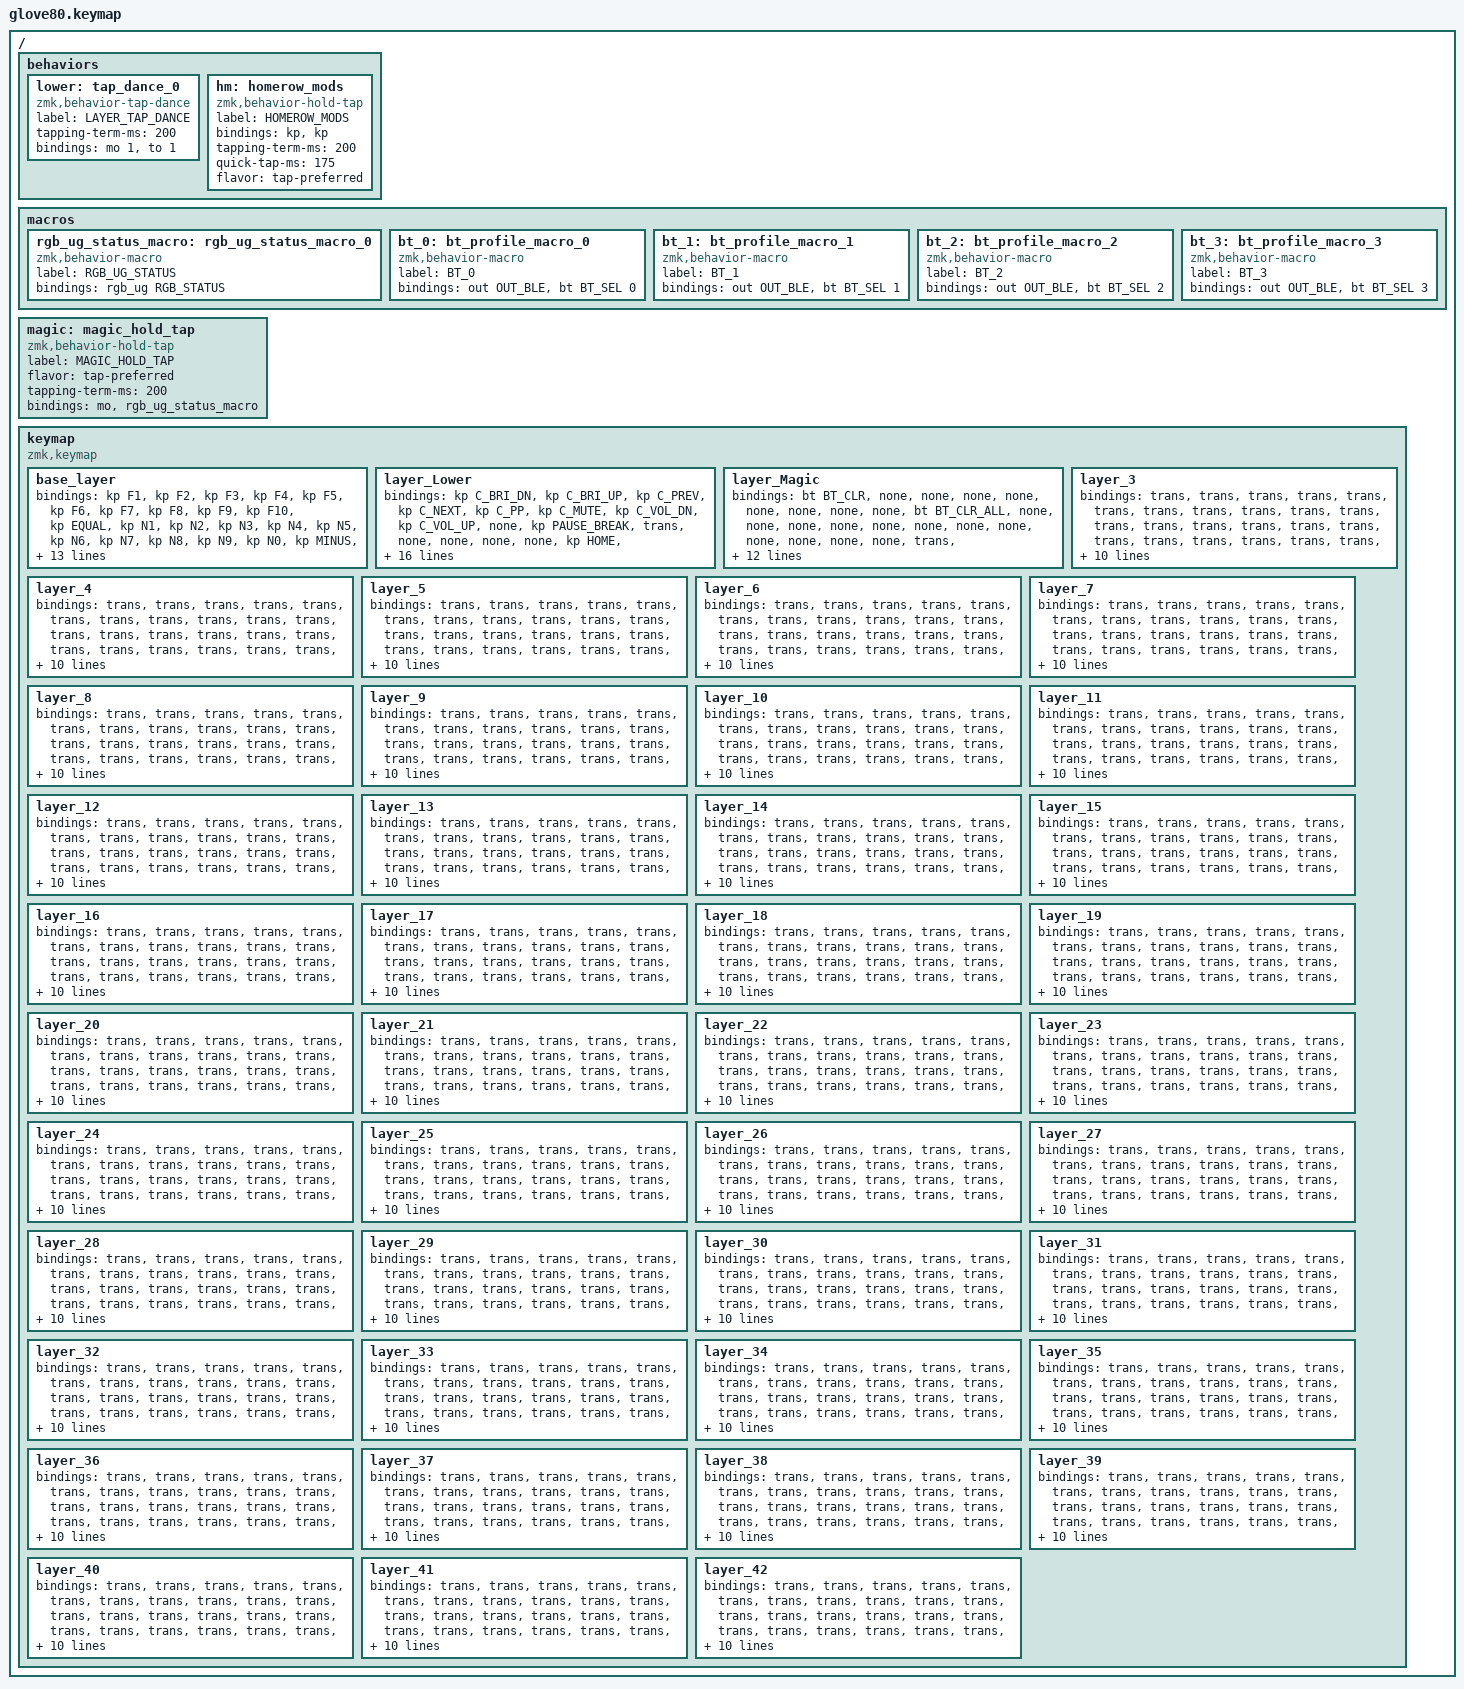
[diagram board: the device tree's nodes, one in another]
/*
 * Copyright (c) 2020 The ZMK Contributors
 * Copyright (c) 2022 Innaworks Development Limited, trading as MoErgo
 *
 * SPDX-License-Identifier: MIT
 */
/* THIS FILE WAS GENERATED BY GLOVE80 LAYOUT EDITOR
 *
 * This file was generated automatically. You may or may not want to
 * edit it directly.
 */

#include <behaviors.dtsi>

/* Include all behaviour includes needed by system behaviors/macros */
/* Include behaviour includes needed by key binds - automatically generated */

#include <dt-bindings/zmk/bt.h>
#include <dt-bindings/zmk/keys.h>
#include <dt-bindings/zmk/outputs.h>
#include <dt-bindings/zmk/rgb.h>

/ {
    /* Glove80 system behavior & macros */

    behaviors {
        // For the "layer" key, it'd nice to be able to use it as either a shift or a toggle.
        // Configure it as a tap dance, so the first tap (or hold) is a &mo and the second tap is a &to

        lower: tap_dance_0 {
            compatible = "zmk,behavior-tap-dance";
            label = "LAYER_TAP_DANCE";
            #binding-cells = <0>;
            tapping-term-ms = <200>;
            bindings = <&mo 1>, <&to 1>;
        };
        hm: homerow_mods {
            compatible = "zmk,behavior-hold-tap";
            label = "HOMEROW_MODS";
            bindings = <&kp>, <&kp>;

            #binding-cells = <2>;
            tapping-term-ms = <200>;
            quick-tap-ms = <175>;
            flavor = "tap-preferred";
        };
    };

    macros {
        rgb_ug_status_macro: rgb_ug_status_macro_0 {
            label = "RGB_UG_STATUS";
            compatible = "zmk,behavior-macro";
            #binding-cells = <0>;
            bindings = <&rgb_ug RGB_STATUS>;
        };
    };

    macros {
        bt_0: bt_profile_macro_0 {
            label = "BT_0";
            compatible = "zmk,behavior-macro";
            #binding-cells = <0>;
            bindings = <&out OUT_BLE &bt BT_SEL 0>;
        };
    };

    macros {
        bt_1: bt_profile_macro_1 {
            label = "BT_1";
            compatible = "zmk,behavior-macro";
            #binding-cells = <0>;
            bindings = <&out OUT_BLE &bt BT_SEL 1>;
        };
    };

    macros {
        bt_2: bt_profile_macro_2 {
            label = "BT_2";
            compatible = "zmk,behavior-macro";
            #binding-cells = <0>;
            bindings = <&out OUT_BLE &bt BT_SEL 2>;
        };
    };

    macros {
        bt_3: bt_profile_macro_3 {
            label = "BT_3";
            compatible = "zmk,behavior-macro";
            #binding-cells = <0>;
            bindings = <&out OUT_BLE &bt BT_SEL 3>;
        };
    };

    magic: magic_hold_tap {
        compatible = "zmk,behavior-hold-tap";
        label = "MAGIC_HOLD_TAP";
        #binding-cells = <2>;
        flavor = "tap-preferred";
        tapping-term-ms = <200>;
        bindings = <&mo>, <&rgb_ug_status_macro>;
    };

    /* Custom Defined Behaviors */
    /* Automatically generated keymap */

    keymap {
        compatible = "zmk,keymap";

        base_layer {
            bindings = <
&kp F1      &kp F2     &kp F3          &kp F4            &kp F5                                                                                                      &kp F6       &kp F7        &kp F8           &kp F9     &kp F10
&kp EQUAL   &kp N1     &kp N2          &kp N3            &kp N4             &kp N5                                                                           &kp N6  &kp N7       &kp N8        &kp N9           &kp N0     &kp MINUS
&kp TAB     &kp Q      &kp W           &kp E             &kp R              &kp T                                                                            &kp Y   &kp U        &kp I         &kp O            &kp P      &kp BSLH
&kp ESC     &kp A      &hm LEFT_ALT S  &hm LCTRL D       &hm RSHFT F        &kp G                                                                            &kp H   &hm RSHFT J  &hm RCTRL K   &hm RIGHT_ALT L  &kp SEMI   &kp SQT
&kp LSHIFT  &kp Z      &kp X           &kp C             &kp V              &kp B   &kp LCTRL  &kp LEFT_ALT  &lt 1 HOME  &kp PAGE_UP    &kp LGUI  &kp RCTRL  &kp N   &kp M        &kp COMMA     &kp DOT          &kp FSLH   &kp RSHFT
&magic 2 0  &kp GRAVE  &kp CAPSLOCK    &kp LEFT_BRACKET  &kp RIGHT_BRACKET          &kp BSPC   &kp DEL       &kp END     &kp PAGE_DOWN  &kp RET   &kp SPACE          &kp LEFT     &kp UP_ARROW  &kp DOWN         &kp RIGHT  &lower
            >;
        };

        layer_Lower {
            bindings = <
&kp C_BRI_DN  &kp C_BRI_UP  &kp C_PREV      &kp C_NEXT      &kp C_PP                                                                                           &kp C_MUTE  &kp C_VOL_DN  &kp C_VOL_UP  &none            &kp PAUSE_BREAK
&trans        &none         &none           &none           &none            &kp HOME                                                   &kp LEFT_PARENTHESIS   &kp KP_NUM  &kp KP_EQUAL  &kp KP_SLASH  &kp KP_MULTIPLY  &kp PRINTSCREEN
&trans        &none         &none           &kp UP_ARROW    &none            &kp END                                                    &kp RIGHT_PARENTHESIS  &kp KP_N7   &kp KP_N8     &kp KP_N9     &kp KP_MINUS     &kp SCROLLLOCK
&trans        &none         &kp LEFT_ARROW  &kp DOWN_ARROW  &kp RIGHT_ARROW  &kp PG_UP                                                  &kp PERCENT            &kp KP_N4   &kp KP_N5     &kp KP_N6     &kp KP_PLUS      &none
&trans        &kp K_APP     &none           &kp F11         &kp F12          &kp PG_DN  &trans  &trans  &trans  &trans  &trans  &trans  &kp COMMA              &kp KP_N1   &kp KP_N2     &kp KP_N3     &kp KP_ENTER     &trans
&magic 2 0    &kp CAPS      &kp INS         &kp F11         &kp F12                     &trans  &trans  &trans  &trans  &trans  &trans                         &kp KP_N0   &kp KP_N0     &kp KP_DOT    &kp KP_ENTER     &trans
            >;
        };

        layer_Magic {
            bindings = <
&bt BT_CLR   &none            &none            &none            &none                                                                                     &none  &none  &none  &none  &bt BT_CLR_ALL
&none        &none            &none            &none            &none            &none                                                             &none  &none  &none  &none  &none  &none
&trans       &rgb_ug RGB_SPI  &rgb_ug RGB_SAI  &rgb_ug RGB_HUI  &rgb_ug RGB_BRI  &rgb_ug RGB_TOG                                                   &none  &none  &none  &none  &none  &none
&bootloader  &rgb_ug RGB_SPD  &rgb_ug RGB_SAD  &rgb_ug RGB_HUD  &rgb_ug RGB_BRD  &rgb_ug RGB_EFF                                                   &none  &none  &none  &none  &none  &bootloader
&reset       &none            &none            &none            &none            &none            &bt_2  &bt_3  &none         &none  &none  &none  &none  &none  &none  &none  &none  &reset
&none        &none            &none            &none            &none                             &bt_0  &bt_1  &out OUT_USB  &none  &none  &none         &none  &none  &none  &none  &none
            >;
        };

        layer_3 {
            bindings = <
&trans  &trans  &trans  &trans  &trans                                                                  &trans  &trans  &trans  &trans  &trans
&trans  &trans  &trans  &trans  &trans  &trans                                                  &trans  &trans  &trans  &trans  &trans  &trans
&trans  &trans  &trans  &trans  &trans  &trans                                                  &trans  &trans  &trans  &trans  &trans  &trans
&trans  &trans  &trans  &trans  &trans  &trans                                                  &trans  &trans  &trans  &trans  &trans  &trans
&trans  &trans  &trans  &trans  &trans  &trans  &trans  &trans  &trans  &trans  &trans  &trans  &trans  &trans  &trans  &trans  &trans  &trans
&trans  &trans  &trans  &trans  &trans          &trans  &trans  &trans  &trans  &trans  &trans          &trans  &trans  &trans  &trans  &trans
            >;
        };

        layer_4 {
            bindings = <
&trans  &trans  &trans  &trans  &trans                                                                  &trans  &trans  &trans  &trans  &trans
&trans  &trans  &trans  &trans  &trans  &trans                                                  &trans  &trans  &trans  &trans  &trans  &trans
&trans  &trans  &trans  &trans  &trans  &trans                                                  &trans  &trans  &trans  &trans  &trans  &trans
&trans  &trans  &trans  &trans  &trans  &trans                                                  &trans  &trans  &trans  &trans  &trans  &trans
&trans  &trans  &trans  &trans  &trans  &trans  &trans  &trans  &trans  &trans  &trans  &trans  &trans  &trans  &trans  &trans  &trans  &trans
&trans  &trans  &trans  &trans  &trans          &trans  &trans  &trans  &trans  &trans  &trans          &trans  &trans  &trans  &trans  &trans
            >;
        };

        layer_5 {
            bindings = <
&trans  &trans  &trans  &trans  &trans                                                                  &trans  &trans  &trans  &trans  &trans
&trans  &trans  &trans  &trans  &trans  &trans                                                  &trans  &trans  &trans  &trans  &trans  &trans
&trans  &trans  &trans  &trans  &trans  &trans                                                  &trans  &trans  &trans  &trans  &trans  &trans
&trans  &trans  &trans  &trans  &trans  &trans                                                  &trans  &trans  &trans  &trans  &trans  &trans
&trans  &trans  &trans  &trans  &trans  &trans  &trans  &trans  &trans  &trans  &trans  &trans  &trans  &trans  &trans  &trans  &trans  &trans
&trans  &trans  &trans  &trans  &trans          &trans  &trans  &trans  &trans  &trans  &trans          &trans  &trans  &trans  &trans  &trans
            >;
        };

        layer_6 {
            bindings = <
&trans  &trans  &trans  &trans  &trans                                                                  &trans  &trans  &trans  &trans  &trans
&trans  &trans  &trans  &trans  &trans  &trans                                                  &trans  &trans  &trans  &trans  &trans  &trans
&trans  &trans  &trans  &trans  &trans  &trans                                                  &trans  &trans  &trans  &trans  &trans  &trans
&trans  &trans  &trans  &trans  &trans  &trans                                                  &trans  &trans  &trans  &trans  &trans  &trans
&trans  &trans  &trans  &trans  &trans  &trans  &trans  &trans  &trans  &trans  &trans  &trans  &trans  &trans  &trans  &trans  &trans  &trans
&trans  &trans  &trans  &trans  &trans          &trans  &trans  &trans  &trans  &trans  &trans          &trans  &trans  &trans  &trans  &trans
            >;
        };

        layer_7 {
            bindings = <
&trans  &trans  &trans  &trans  &trans                                                                  &trans  &trans  &trans  &trans  &trans
&trans  &trans  &trans  &trans  &trans  &trans                                                  &trans  &trans  &trans  &trans  &trans  &trans
&trans  &trans  &trans  &trans  &trans  &trans                                                  &trans  &trans  &trans  &trans  &trans  &trans
&trans  &trans  &trans  &trans  &trans  &trans                                                  &trans  &trans  &trans  &trans  &trans  &trans
&trans  &trans  &trans  &trans  &trans  &trans  &trans  &trans  &trans  &trans  &trans  &trans  &trans  &trans  &trans  &trans  &trans  &trans
&trans  &trans  &trans  &trans  &trans          &trans  &trans  &trans  &trans  &trans  &trans          &trans  &trans  &trans  &trans  &trans
            >;
        };

        layer_8 {
            bindings = <
&trans  &trans  &trans  &trans  &trans                                                                  &trans  &trans  &trans  &trans  &trans
&trans  &trans  &trans  &trans  &trans  &trans                                                  &trans  &trans  &trans  &trans  &trans  &trans
&trans  &trans  &trans  &trans  &trans  &trans                                                  &trans  &trans  &trans  &trans  &trans  &trans
&trans  &trans  &trans  &trans  &trans  &trans                                                  &trans  &trans  &trans  &trans  &trans  &trans
&trans  &trans  &trans  &trans  &trans  &trans  &trans  &trans  &trans  &trans  &trans  &trans  &trans  &trans  &trans  &trans  &trans  &trans
&trans  &trans  &trans  &trans  &trans          &trans  &trans  &trans  &trans  &trans  &trans          &trans  &trans  &trans  &trans  &trans
            >;
        };

        layer_9 {
            bindings = <
&trans  &trans  &trans  &trans  &trans                                                                  &trans  &trans  &trans  &trans  &trans
&trans  &trans  &trans  &trans  &trans  &trans                                                  &trans  &trans  &trans  &trans  &trans  &trans
&trans  &trans  &trans  &trans  &trans  &trans                                                  &trans  &trans  &trans  &trans  &trans  &trans
&trans  &trans  &trans  &trans  &trans  &trans                                                  &trans  &trans  &trans  &trans  &trans  &trans
&trans  &trans  &trans  &trans  &trans  &trans  &trans  &trans  &trans  &trans  &trans  &trans  &trans  &trans  &trans  &trans  &trans  &trans
&trans  &trans  &trans  &trans  &trans          &trans  &trans  &trans  &trans  &trans  &trans          &trans  &trans  &trans  &trans  &trans
            >;
        };

        layer_10 {
            bindings = <
&trans  &trans  &trans  &trans  &trans                                                                  &trans  &trans  &trans  &trans  &trans
&trans  &trans  &trans  &trans  &trans  &trans                                                  &trans  &trans  &trans  &trans  &trans  &trans
&trans  &trans  &trans  &trans  &trans  &trans                                                  &trans  &trans  &trans  &trans  &trans  &trans
&trans  &trans  &trans  &trans  &trans  &trans                                                  &trans  &trans  &trans  &trans  &trans  &trans
&trans  &trans  &trans  &trans  &trans  &trans  &trans  &trans  &trans  &trans  &trans  &trans  &trans  &trans  &trans  &trans  &trans  &trans
&trans  &trans  &trans  &trans  &trans          &trans  &trans  &trans  &trans  &trans  &trans          &trans  &trans  &trans  &trans  &trans
            >;
        };

        layer_11 {
            bindings = <
&trans  &trans  &trans  &trans  &trans                                                                  &trans  &trans  &trans  &trans  &trans
&trans  &trans  &trans  &trans  &trans  &trans                                                  &trans  &trans  &trans  &trans  &trans  &trans
&trans  &trans  &trans  &trans  &trans  &trans                                                  &trans  &trans  &trans  &trans  &trans  &trans
&trans  &trans  &trans  &trans  &trans  &trans                                                  &trans  &trans  &trans  &trans  &trans  &trans
&trans  &trans  &trans  &trans  &trans  &trans  &trans  &trans  &trans  &trans  &trans  &trans  &trans  &trans  &trans  &trans  &trans  &trans
&trans  &trans  &trans  &trans  &trans          &trans  &trans  &trans  &trans  &trans  &trans          &trans  &trans  &trans  &trans  &trans
            >;
        };

        layer_12 {
            bindings = <
&trans  &trans  &trans  &trans  &trans                                                                  &trans  &trans  &trans  &trans  &trans
&trans  &trans  &trans  &trans  &trans  &trans                                                  &trans  &trans  &trans  &trans  &trans  &trans
&trans  &trans  &trans  &trans  &trans  &trans                                                  &trans  &trans  &trans  &trans  &trans  &trans
&trans  &trans  &trans  &trans  &trans  &trans                                                  &trans  &trans  &trans  &trans  &trans  &trans
&trans  &trans  &trans  &trans  &trans  &trans  &trans  &trans  &trans  &trans  &trans  &trans  &trans  &trans  &trans  &trans  &trans  &trans
&trans  &trans  &trans  &trans  &trans          &trans  &trans  &trans  &trans  &trans  &trans          &trans  &trans  &trans  &trans  &trans
            >;
        };

        layer_13 {
            bindings = <
&trans  &trans  &trans  &trans  &trans                                                                  &trans  &trans  &trans  &trans  &trans
&trans  &trans  &trans  &trans  &trans  &trans                                                  &trans  &trans  &trans  &trans  &trans  &trans
&trans  &trans  &trans  &trans  &trans  &trans                                                  &trans  &trans  &trans  &trans  &trans  &trans
&trans  &trans  &trans  &trans  &trans  &trans                                                  &trans  &trans  &trans  &trans  &trans  &trans
&trans  &trans  &trans  &trans  &trans  &trans  &trans  &trans  &trans  &trans  &trans  &trans  &trans  &trans  &trans  &trans  &trans  &trans
&trans  &trans  &trans  &trans  &trans          &trans  &trans  &trans  &trans  &trans  &trans          &trans  &trans  &trans  &trans  &trans
            >;
        };

        layer_14 {
            bindings = <
&trans  &trans  &trans  &trans  &trans                                                                  &trans  &trans  &trans  &trans  &trans
&trans  &trans  &trans  &trans  &trans  &trans                                                  &trans  &trans  &trans  &trans  &trans  &trans
&trans  &trans  &trans  &trans  &trans  &trans                                                  &trans  &trans  &trans  &trans  &trans  &trans
&trans  &trans  &trans  &trans  &trans  &trans                                                  &trans  &trans  &trans  &trans  &trans  &trans
&trans  &trans  &trans  &trans  &trans  &trans  &trans  &trans  &trans  &trans  &trans  &trans  &trans  &trans  &trans  &trans  &trans  &trans
&trans  &trans  &trans  &trans  &trans          &trans  &trans  &trans  &trans  &trans  &trans          &trans  &trans  &trans  &trans  &trans
            >;
        };

        layer_15 {
            bindings = <
&trans  &trans  &trans  &trans  &trans                                                                  &trans  &trans  &trans  &trans  &trans
&trans  &trans  &trans  &trans  &trans  &trans                                                  &trans  &trans  &trans  &trans  &trans  &trans
&trans  &trans  &trans  &trans  &trans  &trans                                                  &trans  &trans  &trans  &trans  &trans  &trans
&trans  &trans  &trans  &trans  &trans  &trans                                                  &trans  &trans  &trans  &trans  &trans  &trans
&trans  &trans  &trans  &trans  &trans  &trans  &trans  &trans  &trans  &trans  &trans  &trans  &trans  &trans  &trans  &trans  &trans  &trans
&trans  &trans  &trans  &trans  &trans          &trans  &trans  &trans  &trans  &trans  &trans          &trans  &trans  &trans  &trans  &trans
            >;
        };

        layer_16 {
            bindings = <
&trans  &trans  &trans  &trans  &trans                                                                  &trans  &trans  &trans  &trans  &trans
&trans  &trans  &trans  &trans  &trans  &trans                                                  &trans  &trans  &trans  &trans  &trans  &trans
&trans  &trans  &trans  &trans  &trans  &trans                                                  &trans  &trans  &trans  &trans  &trans  &trans
&trans  &trans  &trans  &trans  &trans  &trans                                                  &trans  &trans  &trans  &trans  &trans  &trans
&trans  &trans  &trans  &trans  &trans  &trans  &trans  &trans  &trans  &trans  &trans  &trans  &trans  &trans  &trans  &trans  &trans  &trans
&trans  &trans  &trans  &trans  &trans          &trans  &trans  &trans  &trans  &trans  &trans          &trans  &trans  &trans  &trans  &trans
            >;
        };

        layer_17 {
            bindings = <
&trans  &trans  &trans  &trans  &trans                                                                  &trans  &trans  &trans  &trans  &trans
&trans  &trans  &trans  &trans  &trans  &trans                                                  &trans  &trans  &trans  &trans  &trans  &trans
&trans  &trans  &trans  &trans  &trans  &trans                                                  &trans  &trans  &trans  &trans  &trans  &trans
&trans  &trans  &trans  &trans  &trans  &trans                                                  &trans  &trans  &trans  &trans  &trans  &trans
&trans  &trans  &trans  &trans  &trans  &trans  &trans  &trans  &trans  &trans  &trans  &trans  &trans  &trans  &trans  &trans  &trans  &trans
&trans  &trans  &trans  &trans  &trans          &trans  &trans  &trans  &trans  &trans  &trans          &trans  &trans  &trans  &trans  &trans
            >;
        };

        layer_18 {
            bindings = <
&trans  &trans  &trans  &trans  &trans                                                                  &trans  &trans  &trans  &trans  &trans
&trans  &trans  &trans  &trans  &trans  &trans                                                  &trans  &trans  &trans  &trans  &trans  &trans
&trans  &trans  &trans  &trans  &trans  &trans                                                  &trans  &trans  &trans  &trans  &trans  &trans
&trans  &trans  &trans  &trans  &trans  &trans                                                  &trans  &trans  &trans  &trans  &trans  &trans
&trans  &trans  &trans  &trans  &trans  &trans  &trans  &trans  &trans  &trans  &trans  &trans  &trans  &trans  &trans  &trans  &trans  &trans
&trans  &trans  &trans  &trans  &trans          &trans  &trans  &trans  &trans  &trans  &trans          &trans  &trans  &trans  &trans  &trans
            >;
        };

        layer_19 {
            bindings = <
&trans  &trans  &trans  &trans  &trans                                                                  &trans  &trans  &trans  &trans  &trans
&trans  &trans  &trans  &trans  &trans  &trans                                                  &trans  &trans  &trans  &trans  &trans  &trans
&trans  &trans  &trans  &trans  &trans  &trans                                                  &trans  &trans  &trans  &trans  &trans  &trans
&trans  &trans  &trans  &trans  &trans  &trans                                                  &trans  &trans  &trans  &trans  &trans  &trans
&trans  &trans  &trans  &trans  &trans  &trans  &trans  &trans  &trans  &trans  &trans  &trans  &trans  &trans  &trans  &trans  &trans  &trans
&trans  &trans  &trans  &trans  &trans          &trans  &trans  &trans  &trans  &trans  &trans          &trans  &trans  &trans  &trans  &trans
            >;
        };

        layer_20 {
            bindings = <
&trans  &trans  &trans  &trans  &trans                                                                  &trans  &trans  &trans  &trans  &trans
&trans  &trans  &trans  &trans  &trans  &trans                                                  &trans  &trans  &trans  &trans  &trans  &trans
&trans  &trans  &trans  &trans  &trans  &trans                                                  &trans  &trans  &trans  &trans  &trans  &trans
&trans  &trans  &trans  &trans  &trans  &trans                                                  &trans  &trans  &trans  &trans  &trans  &trans
&trans  &trans  &trans  &trans  &trans  &trans  &trans  &trans  &trans  &trans  &trans  &trans  &trans  &trans  &trans  &trans  &trans  &trans
&trans  &trans  &trans  &trans  &trans          &trans  &trans  &trans  &trans  &trans  &trans          &trans  &trans  &trans  &trans  &trans
            >;
        };

        layer_21 {
            bindings = <
&trans  &trans  &trans  &trans  &trans                                                                  &trans  &trans  &trans  &trans  &trans
&trans  &trans  &trans  &trans  &trans  &trans                                                  &trans  &trans  &trans  &trans  &trans  &trans
&trans  &trans  &trans  &trans  &trans  &trans                                                  &trans  &trans  &trans  &trans  &trans  &trans
&trans  &trans  &trans  &trans  &trans  &trans                                                  &trans  &trans  &trans  &trans  &trans  &trans
&trans  &trans  &trans  &trans  &trans  &trans  &trans  &trans  &trans  &trans  &trans  &trans  &trans  &trans  &trans  &trans  &trans  &trans
&trans  &trans  &trans  &trans  &trans          &trans  &trans  &trans  &trans  &trans  &trans          &trans  &trans  &trans  &trans  &trans
            >;
        };

        layer_22 {
            bindings = <
&trans  &trans  &trans  &trans  &trans                                                                  &trans  &trans  &trans  &trans  &trans
&trans  &trans  &trans  &trans  &trans  &trans                                                  &trans  &trans  &trans  &trans  &trans  &trans
&trans  &trans  &trans  &trans  &trans  &trans                                                  &trans  &trans  &trans  &trans  &trans  &trans
&trans  &trans  &trans  &trans  &trans  &trans                                                  &trans  &trans  &trans  &trans  &trans  &trans
&trans  &trans  &trans  &trans  &trans  &trans  &trans  &trans  &trans  &trans  &trans  &trans  &trans  &trans  &trans  &trans  &trans  &trans
&trans  &trans  &trans  &trans  &trans          &trans  &trans  &trans  &trans  &trans  &trans          &trans  &trans  &trans  &trans  &trans
            >;
        };

        layer_23 {
            bindings = <
&trans  &trans  &trans  &trans  &trans                                                                  &trans  &trans  &trans  &trans  &trans
&trans  &trans  &trans  &trans  &trans  &trans                                                  &trans  &trans  &trans  &trans  &trans  &trans
&trans  &trans  &trans  &trans  &trans  &trans                                                  &trans  &trans  &trans  &trans  &trans  &trans
&trans  &trans  &trans  &trans  &trans  &trans                                                  &trans  &trans  &trans  &trans  &trans  &trans
&trans  &trans  &trans  &trans  &trans  &trans  &trans  &trans  &trans  &trans  &trans  &trans  &trans  &trans  &trans  &trans  &trans  &trans
&trans  &trans  &trans  &trans  &trans          &trans  &trans  &trans  &trans  &trans  &trans          &trans  &trans  &trans  &trans  &trans
            >;
        };

        layer_24 {
            bindings = <
&trans  &trans  &trans  &trans  &trans                                                                  &trans  &trans  &trans  &trans  &trans
&trans  &trans  &trans  &trans  &trans  &trans                                                  &trans  &trans  &trans  &trans  &trans  &trans
&trans  &trans  &trans  &trans  &trans  &trans                                                  &trans  &trans  &trans  &trans  &trans  &trans
&trans  &trans  &trans  &trans  &trans  &trans                                                  &trans  &trans  &trans  &trans  &trans  &trans
&trans  &trans  &trans  &trans  &trans  &trans  &trans  &trans  &trans  &trans  &trans  &trans  &trans  &trans  &trans  &trans  &trans  &trans
&trans  &trans  &trans  &trans  &trans          &trans  &trans  &trans  &trans  &trans  &trans          &trans  &trans  &trans  &trans  &trans
            >;
        };

        layer_25 {
            bindings = <
&trans  &trans  &trans  &trans  &trans                                                                  &trans  &trans  &trans  &trans  &trans
&trans  &trans  &trans  &trans  &trans  &trans                                                  &trans  &trans  &trans  &trans  &trans  &trans
&trans  &trans  &trans  &trans  &trans  &trans                                                  &trans  &trans  &trans  &trans  &trans  &trans
&trans  &trans  &trans  &trans  &trans  &trans                                                  &trans  &trans  &trans  &trans  &trans  &trans
&trans  &trans  &trans  &trans  &trans  &trans  &trans  &trans  &trans  &trans  &trans  &trans  &trans  &trans  &trans  &trans  &trans  &trans
&trans  &trans  &trans  &trans  &trans          &trans  &trans  &trans  &trans  &trans  &trans          &trans  &trans  &trans  &trans  &trans
            >;
        };

        layer_26 {
            bindings = <
&trans  &trans  &trans  &trans  &trans                                                                  &trans  &trans  &trans  &trans  &trans
&trans  &trans  &trans  &trans  &trans  &trans                                                  &trans  &trans  &trans  &trans  &trans  &trans
&trans  &trans  &trans  &trans  &trans  &trans                                                  &trans  &trans  &trans  &trans  &trans  &trans
&trans  &trans  &trans  &trans  &trans  &trans                                                  &trans  &trans  &trans  &trans  &trans  &trans
&trans  &trans  &trans  &trans  &trans  &trans  &trans  &trans  &trans  &trans  &trans  &trans  &trans  &trans  &trans  &trans  &trans  &trans
&trans  &trans  &trans  &trans  &trans          &trans  &trans  &trans  &trans  &trans  &trans          &trans  &trans  &trans  &trans  &trans
            >;
        };

        layer_27 {
            bindings = <
&trans  &trans  &trans  &trans  &trans                                                                  &trans  &trans  &trans  &trans  &trans
&trans  &trans  &trans  &trans  &trans  &trans                                                  &trans  &trans  &trans  &trans  &trans  &trans
&trans  &trans  &trans  &trans  &trans  &trans                                                  &trans  &trans  &trans  &trans  &trans  &trans
&trans  &trans  &trans  &trans  &trans  &trans                                                  &trans  &trans  &trans  &trans  &trans  &trans
&trans  &trans  &trans  &trans  &trans  &trans  &trans  &trans  &trans  &trans  &trans  &trans  &trans  &trans  &trans  &trans  &trans  &trans
&trans  &trans  &trans  &trans  &trans          &trans  &trans  &trans  &trans  &trans  &trans          &trans  &trans  &trans  &trans  &trans
            >;
        };

        layer_28 {
            bindings = <
&trans  &trans  &trans  &trans  &trans                                                                  &trans  &trans  &trans  &trans  &trans
&trans  &trans  &trans  &trans  &trans  &trans                                                  &trans  &trans  &trans  &trans  &trans  &trans
&trans  &trans  &trans  &trans  &trans  &trans                                                  &trans  &trans  &trans  &trans  &trans  &trans
&trans  &trans  &trans  &trans  &trans  &trans                                                  &trans  &trans  &trans  &trans  &trans  &trans
&trans  &trans  &trans  &trans  &trans  &trans  &trans  &trans  &trans  &trans  &trans  &trans  &trans  &trans  &trans  &trans  &trans  &trans
&trans  &trans  &trans  &trans  &trans          &trans  &trans  &trans  &trans  &trans  &trans          &trans  &trans  &trans  &trans  &trans
            >;
        };

        layer_29 {
            bindings = <
&trans  &trans  &trans  &trans  &trans                                                                  &trans  &trans  &trans  &trans  &trans
&trans  &trans  &trans  &trans  &trans  &trans                                                  &trans  &trans  &trans  &trans  &trans  &trans
&trans  &trans  &trans  &trans  &trans  &trans                                                  &trans  &trans  &trans  &trans  &trans  &trans
&trans  &trans  &trans  &trans  &trans  &trans                                                  &trans  &trans  &trans  &trans  &trans  &trans
&trans  &trans  &trans  &trans  &trans  &trans  &trans  &trans  &trans  &trans  &trans  &trans  &trans  &trans  &trans  &trans  &trans  &trans
&trans  &trans  &trans  &trans  &trans          &trans  &trans  &trans  &trans  &trans  &trans          &trans  &trans  &trans  &trans  &trans
            >;
        };

        layer_30 {
            bindings = <
&trans  &trans  &trans  &trans  &trans                                                                  &trans  &trans  &trans  &trans  &trans
&trans  &trans  &trans  &trans  &trans  &trans                                                  &trans  &trans  &trans  &trans  &trans  &trans
&trans  &trans  &trans  &trans  &trans  &trans                                                  &trans  &trans  &trans  &trans  &trans  &trans
&trans  &trans  &trans  &trans  &trans  &trans                                                  &trans  &trans  &trans  &trans  &trans  &trans
&trans  &trans  &trans  &trans  &trans  &trans  &trans  &trans  &trans  &trans  &trans  &trans  &trans  &trans  &trans  &trans  &trans  &trans
&trans  &trans  &trans  &trans  &trans          &trans  &trans  &trans  &trans  &trans  &trans          &trans  &trans  &trans  &trans  &trans
            >;
        };

        layer_31 {
            bindings = <
&trans  &trans  &trans  &trans  &trans                                                                  &trans  &trans  &trans  &trans  &trans
&trans  &trans  &trans  &trans  &trans  &trans                                                  &trans  &trans  &trans  &trans  &trans  &trans
&trans  &trans  &trans  &trans  &trans  &trans                                                  &trans  &trans  &trans  &trans  &trans  &trans
&trans  &trans  &trans  &trans  &trans  &trans                                                  &trans  &trans  &trans  &trans  &trans  &trans
&trans  &trans  &trans  &trans  &trans  &trans  &trans  &trans  &trans  &trans  &trans  &trans  &trans  &trans  &trans  &trans  &trans  &trans
&trans  &trans  &trans  &trans  &trans          &trans  &trans  &trans  &trans  &trans  &trans          &trans  &trans  &trans  &trans  &trans
            >;
        };

        layer_32 {
            bindings = <
&trans  &trans  &trans  &trans  &trans                                                                  &trans  &trans  &trans  &trans  &trans
&trans  &trans  &trans  &trans  &trans  &trans                                                  &trans  &trans  &trans  &trans  &trans  &trans
&trans  &trans  &trans  &trans  &trans  &trans                                                  &trans  &trans  &trans  &trans  &trans  &trans
&trans  &trans  &trans  &trans  &trans  &trans                                                  &trans  &trans  &trans  &trans  &trans  &trans
&trans  &trans  &trans  &trans  &trans  &trans  &trans  &trans  &trans  &trans  &trans  &trans  &trans  &trans  &trans  &trans  &trans  &trans
&trans  &trans  &trans  &trans  &trans          &trans  &trans  &trans  &trans  &trans  &trans          &trans  &trans  &trans  &trans  &trans
            >;
        };

        layer_33 {
            bindings = <
&trans  &trans  &trans  &trans  &trans                                                                  &trans  &trans  &trans  &trans  &trans
&trans  &trans  &trans  &trans  &trans  &trans                                                  &trans  &trans  &trans  &trans  &trans  &trans
&trans  &trans  &trans  &trans  &trans  &trans                                                  &trans  &trans  &trans  &trans  &trans  &trans
&trans  &trans  &trans  &trans  &trans  &trans                                                  &trans  &trans  &trans  &trans  &trans  &trans
&trans  &trans  &trans  &trans  &trans  &trans  &trans  &trans  &trans  &trans  &trans  &trans  &trans  &trans  &trans  &trans  &trans  &trans
&trans  &trans  &trans  &trans  &trans          &trans  &trans  &trans  &trans  &trans  &trans          &trans  &trans  &trans  &trans  &trans
            >;
        };

        layer_34 {
            bindings = <
&trans  &trans  &trans  &trans  &trans                                                                  &trans  &trans  &trans  &trans  &trans
&trans  &trans  &trans  &trans  &trans  &trans                                                  &trans  &trans  &trans  &trans  &trans  &trans
&trans  &trans  &trans  &trans  &trans  &trans                                                  &trans  &trans  &trans  &trans  &trans  &trans
&trans  &trans  &trans  &trans  &trans  &trans                                                  &trans  &trans  &trans  &trans  &trans  &trans
&trans  &trans  &trans  &trans  &trans  &trans  &trans  &trans  &trans  &trans  &trans  &trans  &trans  &trans  &trans  &trans  &trans  &trans
&trans  &trans  &trans  &trans  &trans          &trans  &trans  &trans  &trans  &trans  &trans          &trans  &trans  &trans  &trans  &trans
            >;
        };

        layer_35 {
            bindings = <
&trans  &trans  &trans  &trans  &trans                                                                  &trans  &trans  &trans  &trans  &trans
&trans  &trans  &trans  &trans  &trans  &trans                                                  &trans  &trans  &trans  &trans  &trans  &trans
&trans  &trans  &trans  &trans  &trans  &trans                                                  &trans  &trans  &trans  &trans  &trans  &trans
&trans  &trans  &trans  &trans  &trans  &trans                                                  &trans  &trans  &trans  &trans  &trans  &trans
&trans  &trans  &trans  &trans  &trans  &trans  &trans  &trans  &trans  &trans  &trans  &trans  &trans  &trans  &trans  &trans  &trans  &trans
&trans  &trans  &trans  &trans  &trans          &trans  &trans  &trans  &trans  &trans  &trans          &trans  &trans  &trans  &trans  &trans
            >;
        };

        layer_36 {
            bindings = <
&trans  &trans  &trans  &trans  &trans                                                                  &trans  &trans  &trans  &trans  &trans
&trans  &trans  &trans  &trans  &trans  &trans                                                  &trans  &trans  &trans  &trans  &trans  &trans
&trans  &trans  &trans  &trans  &trans  &trans                                                  &trans  &trans  &trans  &trans  &trans  &trans
&trans  &trans  &trans  &trans  &trans  &trans                                                  &trans  &trans  &trans  &trans  &trans  &trans
&trans  &trans  &trans  &trans  &trans  &trans  &trans  &trans  &trans  &trans  &trans  &trans  &trans  &trans  &trans  &trans  &trans  &trans
&trans  &trans  &trans  &trans  &trans          &trans  &trans  &trans  &trans  &trans  &trans          &trans  &trans  &trans  &trans  &trans
            >;
        };

        layer_37 {
            bindings = <
&trans  &trans  &trans  &trans  &trans                                                                  &trans  &trans  &trans  &trans  &trans
&trans  &trans  &trans  &trans  &trans  &trans                                                  &trans  &trans  &trans  &trans  &trans  &trans
&trans  &trans  &trans  &trans  &trans  &trans                                                  &trans  &trans  &trans  &trans  &trans  &trans
&trans  &trans  &trans  &trans  &trans  &trans                                                  &trans  &trans  &trans  &trans  &trans  &trans
&trans  &trans  &trans  &trans  &trans  &trans  &trans  &trans  &trans  &trans  &trans  &trans  &trans  &trans  &trans  &trans  &trans  &trans
&trans  &trans  &trans  &trans  &trans          &trans  &trans  &trans  &trans  &trans  &trans          &trans  &trans  &trans  &trans  &trans
            >;
        };

        layer_38 {
            bindings = <
&trans  &trans  &trans  &trans  &trans                                                                  &trans  &trans  &trans  &trans  &trans
&trans  &trans  &trans  &trans  &trans  &trans                                                  &trans  &trans  &trans  &trans  &trans  &trans
&trans  &trans  &trans  &trans  &trans  &trans                                                  &trans  &trans  &trans  &trans  &trans  &trans
&trans  &trans  &trans  &trans  &trans  &trans                                                  &trans  &trans  &trans  &trans  &trans  &trans
&trans  &trans  &trans  &trans  &trans  &trans  &trans  &trans  &trans  &trans  &trans  &trans  &trans  &trans  &trans  &trans  &trans  &trans
&trans  &trans  &trans  &trans  &trans          &trans  &trans  &trans  &trans  &trans  &trans          &trans  &trans  &trans  &trans  &trans
            >;
        };

        layer_39 {
            bindings = <
&trans  &trans  &trans  &trans  &trans                                                                  &trans  &trans  &trans  &trans  &trans
&trans  &trans  &trans  &trans  &trans  &trans                                                  &trans  &trans  &trans  &trans  &trans  &trans
&trans  &trans  &trans  &trans  &trans  &trans                                                  &trans  &trans  &trans  &trans  &trans  &trans
&trans  &trans  &trans  &trans  &trans  &trans                                                  &trans  &trans  &trans  &trans  &trans  &trans
&trans  &trans  &trans  &trans  &trans  &trans  &trans  &trans  &trans  &trans  &trans  &trans  &trans  &trans  &trans  &trans  &trans  &trans
&trans  &trans  &trans  &trans  &trans          &trans  &trans  &trans  &trans  &trans  &trans          &trans  &trans  &trans  &trans  &trans
            >;
        };

        layer_40 {
            bindings = <
&trans  &trans  &trans  &trans  &trans                                                                  &trans  &trans  &trans  &trans  &trans
&trans  &trans  &trans  &trans  &trans  &trans                                                  &trans  &trans  &trans  &trans  &trans  &trans
&trans  &trans  &trans  &trans  &trans  &trans                                                  &trans  &trans  &trans  &trans  &trans  &trans
&trans  &trans  &trans  &trans  &trans  &trans                                                  &trans  &trans  &trans  &trans  &trans  &trans
&trans  &trans  &trans  &trans  &trans  &trans  &trans  &trans  &trans  &trans  &trans  &trans  &trans  &trans  &trans  &trans  &trans  &trans
&trans  &trans  &trans  &trans  &trans          &trans  &trans  &trans  &trans  &trans  &trans          &trans  &trans  &trans  &trans  &trans
            >;
        };

        layer_41 {
            bindings = <
&trans  &trans  &trans  &trans  &trans                                                                  &trans  &trans  &trans  &trans  &trans
&trans  &trans  &trans  &trans  &trans  &trans                                                  &trans  &trans  &trans  &trans  &trans  &trans
&trans  &trans  &trans  &trans  &trans  &trans                                                  &trans  &trans  &trans  &trans  &trans  &trans
&trans  &trans  &trans  &trans  &trans  &trans                                                  &trans  &trans  &trans  &trans  &trans  &trans
&trans  &trans  &trans  &trans  &trans  &trans  &trans  &trans  &trans  &trans  &trans  &trans  &trans  &trans  &trans  &trans  &trans  &trans
&trans  &trans  &trans  &trans  &trans          &trans  &trans  &trans  &trans  &trans  &trans          &trans  &trans  &trans  &trans  &trans
            >;
        };

        layer_42 {
            bindings = <
&trans  &trans  &trans  &trans  &trans                                                                  &trans  &trans  &trans  &trans  &trans
&trans  &trans  &trans  &trans  &trans  &trans                                                  &trans  &trans  &trans  &trans  &trans  &trans
&trans  &trans  &trans  &trans  &trans  &trans                                                  &trans  &trans  &trans  &trans  &trans  &trans
&trans  &trans  &trans  &trans  &trans  &trans                                                  &trans  &trans  &trans  &trans  &trans  &trans
&trans  &trans  &trans  &trans  &trans  &trans  &trans  &trans  &trans  &trans  &trans  &trans  &trans  &trans  &trans  &trans  &trans  &trans
&trans  &trans  &trans  &trans  &trans          &trans  &trans  &trans  &trans  &trans  &trans          &trans  &trans  &trans  &trans  &trans
            >;
        };
    };
};
